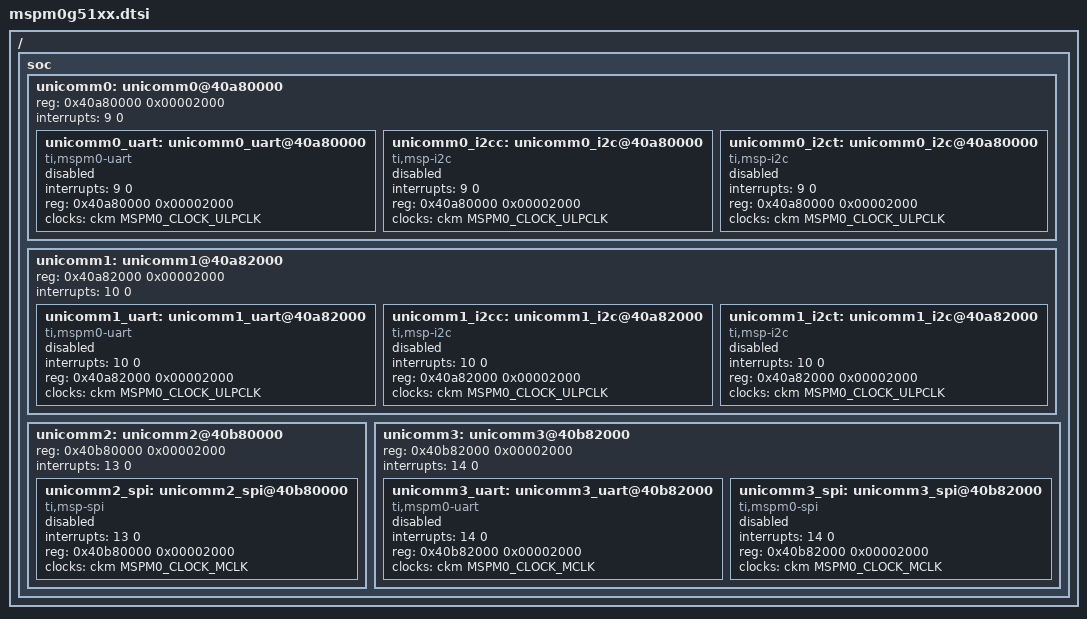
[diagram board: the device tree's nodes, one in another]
/*
 * Copyright (c) 2025 Texas Instruments
 *
 * SPDX-License-Identifier: Apache-2.0
 */

#include <ti/mspm0/g/mspm0g.dtsi>
#include <zephyr/dt-bindings/i2c/i2c.h>

/delete-node/ &uart0;
/delete-node/ &uart1;
/delete-node/ &uart2;
/delete-node/ &uart3;
/delete-node/ &spi0;
/delete-node/ &spi1;
/delete-node/ &tima1;
/delete-node/ &timg12;

/ {
	soc {
		unicomm0: unicomm0@40a80000 {
			reg = <0x40a80000 0x00002000>;
			interrupts = <9 0>;
			#address-cells = <1>;
			#size-cells = <1>;

			unicomm0_uart: unicomm0_uart@40a80000 {
				compatible = "ti,mspm0-uart";
				interrupts = <9 0>;
				reg = <0x40a80000 0x00002000>;
				clocks = <&ckm MSPM0_CLOCK_ULPCLK>;
				status = "disabled";
			};

			unicomm0_i2cc: unicomm0_i2c@40a80000 {
				compatible = "ti,msp-i2c";
				interrupts = <9 0>;
				reg = <0x40a80000 0x00002000>;
				clocks = <&ckm MSPM0_CLOCK_ULPCLK>;
				status = "disabled";
			};

			unicomm0_i2ct: unicomm0_i2c@40a80000 {
				compatible = "ti,msp-i2c";
				interrupts = <9 0>;
				reg = <0x40a80000 0x00002000>;
				clocks = <&ckm MSPM0_CLOCK_ULPCLK>;
				status = "disabled";
			};
		};

		unicomm1: unicomm1@40a82000 {
			reg = <0x40a82000 0x00002000>;
			interrupts = <10 0>;
			#address-cells = <1>;
			#size-cells = <1>;

			unicomm1_uart: unicomm1_uart@40a82000 {
				compatible = "ti,mspm0-uart";
				interrupts = <10 0>;
				reg = <0x40a82000 0x00002000>;
				clocks = <&ckm MSPM0_CLOCK_ULPCLK>;
				status = "disabled";
			};

			unicomm1_i2cc: unicomm1_i2c@40a82000 {
				compatible = "ti,msp-i2c";
				interrupts = <10 0>;
				reg = <0x40a82000 0x00002000>;
				clocks = <&ckm MSPM0_CLOCK_ULPCLK>;
				status = "disabled";
			};

			unicomm1_i2ct: unicomm1_i2c@40a82000 {
				compatible = "ti,msp-i2c";
				interrupts = <10 0>;
				reg = <0x40a82000 0x00002000>;
				clocks = <&ckm MSPM0_CLOCK_ULPCLK>;
				status = "disabled";
			};
		};

		unicomm2: unicomm2@40b80000 {
			reg = <0x40b80000 0x00002000>;
			interrupts = <13 0>;
			#address-cells = <1>;
			#size-cells = <1>;

			unicomm2_spi: unicomm2_spi@40b80000 {
				compatible = "ti,msp-spi";
				interrupts = <13 0>;
				reg = <0x40b80000 0x00002000>;
				#address-cells = <1>;
				#size-cells = <0>;
				clocks = <&ckm MSPM0_CLOCK_MCLK>;
				status = "disabled";
			};
		};

		unicomm3: unicomm3@40b82000 {
			reg = <0x40b82000 0x00002000>;
			interrupts = <14 0>;
			#address-cells = <1>;
			#size-cells = <1>;

			unicomm3_uart: unicomm3_uart@40b82000 {
				compatible = "ti,mspm0-uart";
				interrupts = <14 0>;
				reg = <0x40b82000 0x00002000>;
				clocks = <&ckm MSPM0_CLOCK_MCLK>;
				status = "disabled";
			};

			unicomm3_spi: unicomm3_spi@40b82000 {
				compatible = "ti,mspm0-spi";
				interrupts = <14 0>;
				reg = <0x40b82000 0x00002000>;
				#address-cells = <1>;
				#size-cells = <0>;
				clocks = <&ckm MSPM0_CLOCK_MCLK>;
				status = "disabled";
			};
		};
	};
};
